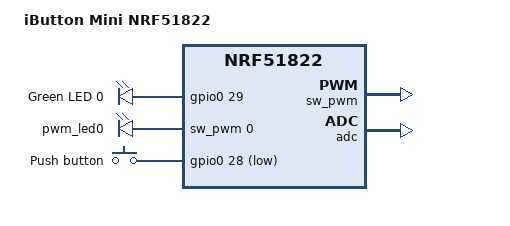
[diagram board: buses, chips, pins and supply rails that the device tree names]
/*
 * Copyright (c) 2017 Linaro Limited
 *
 * SPDX-License-Identifier: Apache-2.0
 */

/dts-v1/;
#include <nordic/nrf51822_qfaa.dtsi>
#include "ibuttonmini_nrf51822-pinctrl.dtsi"
#include <zephyr/dt-bindings/input/input-event-codes.h>

/ {
	model = "iButton Mini NRF51822";
	compatible = "nordic,ibuttonmini";

	chosen {
		zephyr,sram = &sram0;
		zephyr,flash = &flash0;
		zephyr,code-partition = &code_partition;
		zephyr,settings-partition = &storage_partition;
		zephyr,console = &uart0;
		zephyr,shell-uart = &uart0;
		zephyr,uart-mcumgr = &uart0;
		zephyr,bt-mon-uart = &uart0;
		zephyr,bt-c2h-uart = &uart0;
	};

	leds {
		compatible = "gpio-leds";

		led0: led_0 {
			gpios = <&gpio0 29 GPIO_ACTIVE_HIGH>;
			label = "Green LED 0";
		};

	};

	pwmleds {
		compatible = "pwm-leds";

		pwm_led0: pwm_led_0 {
			pwms = <&sw_pwm 0 PWM_MSEC(20) PWM_POLARITY_INVERTED>;
		};
	};

	buttons {
		compatible = "gpio-keys";

		button0: button_0 {
			gpios = <&gpio0 28 (GPIO_PULL_UP | GPIO_ACTIVE_LOW)>;
			label = "Push button";
			zephyr,code = <INPUT_KEY_0>;
		};

	};

	/* These aliases are provided for compatibility with samples */
	aliases {
		led0 = &led0;
		pwm-led0 = &pwm_led0;
		sw0 = &button0;
		watchdog0 = &wdt0;
	};
};

/*&uart0 {
	current-speed = <115200>;
	status = "okay";
	pinctrl-0 = <&uart0_default>;
	pinctrl-1 = <&uart0_sleep>;
	pinctrl-names = "default", "sleep";
};*/

&sw_pwm {
	status ="okay";
	channel-gpios = <&gpio0 21 PWM_POLARITY_INVERTED>;
	clock-prescaler = <8>;
};

&gpiote {
	status = "okay";
};

&gpio0 {
	status = "okay";
};

&adc {
	status = "okay";
};

&flash0 {
	partitions {
		compatible = "fixed-partitions";
		#address-cells = <1>;
		#size-cells = <1>;

		code_partition: partition@0 {
			label = "code_partition";
			reg = <0x00000000 0x30000>;
		};

		storage_partition: partition@30000 {
			label = "storage";
			reg = <0x30000 0x10000>;
		};
	};
};
